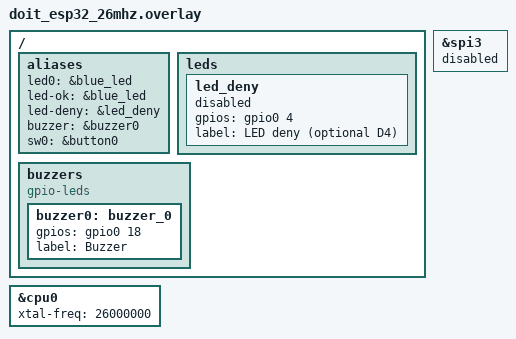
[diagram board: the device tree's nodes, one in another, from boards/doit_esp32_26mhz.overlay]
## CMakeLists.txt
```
# SPDX-License-Identifier: Apache-2.0

cmake_minimum_required(VERSION 3.20.0)
set(DTC_OVERLAY_FILE boards/doit_esp32_26mhz.overlay) #devicetree overlay file
find_package(Zephyr REQUIRED HINTS $ENV{ZEPHYR_BASE})
project(epi_guard)

target_sources(app PRIVATE
	src/main.c
	src/zbus_channels.c
	src/api_client.c
	src/validator.c
	src/actuator.c
	src/actuator_feedback.c
	src/net.c
	src/epi_state.c
	src/epi_names.c
	src/epi_shell.c
	src/epi_config.c
)

if(CONFIG_SETTINGS)
	target_sources(app PRIVATE src/epi_settings.c)
endif()

if(CONFIG_EPI_API_USE_MOCK)
	target_sources(app PRIVATE src/api_client_mock.c)
else()
	target_sources(app PRIVATE src/api_client_http.c)
endif()

if(CONFIG_EPI_HTTP_SERVER OR NOT CONFIG_EPI_API_USE_MOCK)
	target_sources(app PRIVATE src/json_codec.c)
endif()

if(CONFIG_EPI_HTTP_SERVER)
	target_sources(app PRIVATE src/net_http.c src/dashboard_embed.c)
endif()
```

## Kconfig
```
mainmenu "EPI Guard"

source "Kconfig.zephyr"

config EPI_API_USE_MOCK
	bool "Usar mock local da API (sem rede)"
	default y
	help
	  Quando ativo, api_check() usa logica embutida (M1/M2).
	  Desative para cliente HTTP real (M3) — requer WiFi (M4) no hardware.

config EPI_HTTP_SERVER
	bool "Servidor HTTP dashboard (sockets TCP)"
	default n
	depends on NETWORKING && NET_TCP && NET_SOCKETS
	help
	  Servidor HTTP simples em :80 para dashboard e POST /verify.
	  Usa sockets POSIX (mais estavel que CONFIG_HTTP_SERVER no ESP32).
```

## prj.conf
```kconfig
# Core
CONFIG_ZBUS=y
CONFIG_ZBUS_CHANNEL_NAME=y
CONFIG_SHELL=y
CONFIG_LOG=y
CONFIG_LOG_DEFAULT_LEVEL=3

# Console (UART via USB-serial)
CONFIG_CONSOLE=y
CONFIG_UART_CONSOLE=y
CONFIG_SERIAL=y

# GPIO (LED built-in — feedback visual no M1)
CONFIG_GPIO=y

# Stacks
CONFIG_MAIN_STACK_SIZE=2048
CONFIG_SYSTEM_WORKQUEUE_STACK_SIZE=2048

# Shell — edicao de linha (backspace/setas) via VT100
CONFIG_SHELL_VT100_COMMANDS=y
```

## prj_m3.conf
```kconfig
# M3 — cliente HTTP + JSON (combinar com prj.conf; WiFi em prj_wifi.conf)

CONFIG_EPI_API_USE_MOCK=n

# Rede
CONFIG_NETWORKING=y
CONFIG_NET_IPV4=y
CONFIG_NET_IPV6=n
CONFIG_NET_TCP=y
CONFIG_NET_SOCKETS=y
CONFIG_NET_DHCPV4=y
CONFIG_POSIX_API=y
CONFIG_ZVFS_POLL_MAX=4

CONFIG_NET_PKT_RX_COUNT=10
CONFIG_NET_PKT_TX_COUNT=10
CONFIG_NET_BUF_RX_COUNT=20
CONFIG_NET_BUF_TX_COUNT=20
CONFIG_NET_MAX_CONTEXTS=8

CONFIG_HEAP_MEM_POOL_SIZE=65536
CONFIG_MAIN_STACK_SIZE=4096
CONFIG_SYSTEM_WORKQUEUE_STACK_SIZE=4096

# HTTP + JSON
CONFIG_HTTP_CLIENT=y
CONFIG_JSON_LIBRARY=y

# Stacks das threads de rede
CONFIG_NET_TX_STACK_SIZE=2048
CONFIG_NET_RX_STACK_SIZE=2048

CONFIG_TEST_RANDOM_GENERATOR=y
```

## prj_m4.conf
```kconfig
# M4 — settings NVS + WiFi (combinar com prj_m3.conf)

CONFIG_SETTINGS=y
CONFIG_FLASH=y
CONFIG_FLASH_MAP=y
CONFIG_NVS=y
CONFIG_SETTINGS_NVS=y

CONFIG_NET_MGMT=y
CONFIG_NET_MGMT_EVENT=y

CONFIG_WIFI=y
CONFIG_WIFI_LOG_LEVEL_ERR=y
CONFIG_NET_L2_WIFI_MGMT=y
CONFIG_NET_L2_WIFI_SHELL=y
CONFIG_NET_MGMT_EVENT_QUEUE_TIMEOUT=5000
CONFIG_NET_MGMT_EVENT_QUEUE_SIZE=16

CONFIG_NET_SHELL=y
CONFIG_SHELL_STACK_SIZE=4096
CONFIG_COMMON_LIBC_MALLOC_ARENA_SIZE=8192
```

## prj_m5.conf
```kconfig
# M5 — dashboard HTTP via sockets (combinar com prj.conf; prj_m3.conf; prj_m4.conf)

CONFIG_EPI_HTTP_SERVER=y

# Evita acumulo de sockets TIME_WAIT durante testes repetidos no browser
CONFIG_NET_TCP_TIME_WAIT_DELAY=0

# Servidor HTTP (listen + cliente) + cliente API outbound ao mesmo tempo
CONFIG_NET_MAX_CONN=8
CONFIG_NET_MAX_CONTEXTS=12
CONFIG_NET_PKT_RX_COUNT=16
CONFIG_NET_PKT_TX_COUNT=16
CONFIG_NET_BUF_RX_COUNT=32
CONFIG_NET_BUF_TX_COUNT=32
CONFIG_ZVFS_POLL_MAX=8
```

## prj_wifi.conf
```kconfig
# WiFi ESP32 — usar junto com prj_m3.conf (marco M4 completa settings)

CONFIG_WIFI=y
CONFIG_WIFI_LOG_LEVEL_ERR=y
CONFIG_NET_L2_WIFI_MGMT=y
CONFIG_NET_L2_WIFI_SHELL=y
CONFIG_NET_MGMT_EVENT_QUEUE_TIMEOUT=5000
CONFIG_NET_MGMT_EVENT_QUEUE_SIZE=16

CONFIG_NET_SHELL=y
```

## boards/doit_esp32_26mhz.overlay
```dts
/*
 * DOIT ESP32 DevKit — cristal 26 MHz + perifericos EPI Guard.
 *
 * D18 da placa = GPIO18 (buzzer ativo). SPI3 usa GPIO18 por padrao — desabilitado.
 */

#include <zephyr/dt-bindings/gpio/gpio.h>

&cpu0 {
	xtal-freq = <26000000>;
};

&spi3 {
	status = "disabled";
};

/ {
	aliases {
		led0     = &blue_led;
		led-ok   = &blue_led;
		led-deny = &led_deny;
		buzzer   = &buzzer0;
		sw0      = &button0;
	};

	leds {
		led_deny: led_deny {
			gpios = <&gpio0 4 GPIO_ACTIVE_HIGH>;
			label = "LED deny (optional D4)";
			status = "disabled";
		};
	};

	buzzers {
		compatible = "gpio-leds";

		buzzer0: buzzer_0 {
			gpios = <&gpio0 18 GPIO_ACTIVE_HIGH>;
			label = "Buzzer";
		};
	};
};
```

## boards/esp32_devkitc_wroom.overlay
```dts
/*
 * Referencia generica do plano (§5.6) para esp32_devkitc_wroom.
 *
 * Placa DOIT usada no projeto: boards/doit_esp32_26mhz.overlay
 * (CMakeLists.txt aponta DTC_OVERLAY_FILE para esse arquivo).
 *
 * Para montar LED vermelho opcional (led-deny), habilite o no em doit_esp32_26mhz.overlay:
 *   status = "okay";  no nó led_deny (GPIO4 / D4).
 */
```

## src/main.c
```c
/*
 * SPDX-License-Identifier: Apache-2.0
 */

#include <zephyr/kernel.h>
#include <zephyr/logging/log.h>

#if IS_ENABLED(CONFIG_SETTINGS)
#include "epi_config.h"
#include "epi_settings.h"
#endif

#if IS_ENABLED(CONFIG_EPI_HTTP_SERVER)
#include "net_http.h"
#endif

LOG_MODULE_REGISTER(main, LOG_LEVEL_INF);

int main(void)
{
#if IS_ENABLED(CONFIG_SETTINGS)
	int rc;

	rc = epi_settings_init();
	if (rc < 0) {
		LOG_ERR("settings init failed: %d", rc);
	} else {
		rc = epi_settings_load();
		if (rc < 0) {
			LOG_WRN("settings load failed: %d", rc);
		}
		epi_config_sync_from_settings();
	}
#endif

	LOG_INF("EPI Guard firmware - marco M6");
#if IS_ENABLED(CONFIG_EPI_API_USE_MOCK)
	LOG_INF("API: mock local (epi verify sem rede)");
#else
	LOG_INF("API: HTTP client (epi api http://<IP>:3000)");
#endif
#if IS_ENABLED(CONFIG_WIFI)
	LOG_INF("WiFi: epi wifi <ssid> <psk> | epi net");
#endif
#if IS_ENABLED(CONFIG_EPI_HTTP_SERVER)
	LOG_INF("Dashboard: sobe apos WiFi/DHCP (epi status)");
#else
	LOG_INF("Teste: epi verify Gabriel Capacete,Oculos,Cinto,Bota");
#endif

	return 0;
}
```

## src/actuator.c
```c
/*
 * SPDX-License-Identifier: Apache-2.0
 */

#include "actuator_feedback.h"
#include "epi_state.h"
#include "zbus_channels.h"

#include <zephyr/drivers/gpio.h>
#include <zephyr/kernel.h>
#include <zephyr/logging/log.h>
#include <zephyr/zbus/zbus.h>

LOG_MODULE_REGISTER(actuator, LOG_LEVEL_INF);

extern struct zbus_observer actuator_sub;

#define LED0_NODE   DT_ALIAS(led0)
#define BUZZER_NODE DT_ALIAS(buzzer)
#define SW0_NODE    DT_ALIAS(sw0)

#if DT_NODE_HAS_STATUS(LED0_NODE, okay)
static const struct gpio_dt_spec led = GPIO_DT_SPEC_GET(LED0_NODE, gpios);
#define EPI_HAS_LED 1
#else
#define EPI_HAS_LED 0
#endif

#if DT_NODE_HAS_STATUS(BUZZER_NODE, okay)
static const struct gpio_dt_spec buzzer = GPIO_DT_SPEC_GET(BUZZER_NODE, gpios);
#define EPI_HAS_BUZZER 1
#else
#define EPI_HAS_BUZZER 0
#endif

#if DT_NODE_HAS_STATUS(SW0_NODE, okay)
static const struct gpio_dt_spec button = GPIO_DT_SPEC_GET(SW0_NODE, gpios);
#define EPI_HAS_BUTTON 1
#else
#define EPI_HAS_BUTTON 0
#endif

static bool led_ready;
static bool buzzer_ready;
static bool button_ready;

struct feedback_ctx {
	struct k_work work;
	struct verify_result result;
};

static struct feedback_ctx feedback;

static int actuator_gpio_init(void)
{
#if EPI_HAS_LED
	if (gpio_is_ready_dt(&led) && gpio_pin_configure_dt(&led, GPIO_OUTPUT_INACTIVE) == 0) {
		led_ready = true;
	} else {
		LOG_WRN("led0 indisponivel");
	}
#endif

#if EPI_HAS_BUZZER
	if (gpio_is_ready_dt(&buzzer) &&
	    gpio_pin_configure_dt(&buzzer, GPIO_OUTPUT_INACTIVE) == 0) {
		buzzer_ready = true;
		LOG_INF("buzzer em GPIO%d", buzzer.pin);
	} else {
		LOG_WRN("buzzer indisponivel");
	}
#endif

#if EPI_HAS_BUTTON
	if (gpio_is_ready_dt(&button) &&
	    gpio_pin_configure_dt(&button, GPIO_INPUT) == 0) {
		button_ready = true;
		LOG_INF("botao BOOT em GPIO%d", button.pin);
	} else {
		LOG_WRN("botao sw0 indisponivel");
	}
#endif

	return 0;
}

static void led_on(void)
{
#if EPI_HAS_LED
	if (led_ready) {
		gpio_pin_set_dt(&led, 1);
	}
#endif
}

static void led_off(void)
{
#if EPI_HAS_LED
	if (led_ready) {
		gpio_pin_set_dt(&led, 0);
	}
#endif
}

static void buzzer_on(void)
{
#if EPI_HAS_BUZZER
	if (buzzer_ready) {
		gpio_pin_set_dt(&buzzer, 1);
	}
#endif
}

static void buzzer_off(void)
{
#if EPI_HAS_BUZZER
	if (buzzer_ready) {
		gpio_pin_set_dt(&buzzer, 0);
	}
#endif
}

static void beep_ms(uint32_t ms)
{
	buzzer_on();
	k_msleep(ms);
	buzzer_off();
}

static bool button_pressed(void)
{
#if EPI_HAS_BUTTON
	int val;

	if (!button_ready) {
		return false;
	}

	val = gpio_pin_get_dt(&button);
	if (val < 0) {
		return false;
	}

	/* gpio_pin_get_dt: 1 = ativo (pressionado com GPIO_ACTIVE_LOW no DT) */
	return val != 0;
#else
	return false;
#endif
}

static void log_missing(const struct verify_result *res)
{
	if (res->missing_count == 0) {
		return;
	}

	LOG_INF("Faltando:");
	for (uint8_t i = 0; i < res->missing_count; i++) {
		LOG_INF("  - %s", res->missing[i]);
	}
}

static void run_allowed(void)
{
	LOG_INF("LIBERADO - bip curto, LED fixo ~3 s");
	beep_ms(120);
	led_on();
	k_msleep(3000);
	led_off();
}

static void run_denied(const struct verify_result *res)
{
	LOG_INF("NEGADO - bip longo, LED piscando ~3 s");
	log_missing(res);

	beep_ms(900);

	for (int i = 0; i < 6; i++) {
		led_on();
		k_msleep(250);
		led_off();
		k_msleep(250);
	}
}

static void run_unknown(void)
{
	LOG_INF("NAO CADASTRADO - LED azul piscando, buzzer continuo (pressione BOOT para parar)");

	while (!button_pressed()) {
		buzzer_on();
		k_msleep(120);
		buzzer_off();
		k_msleep(80);

		led_on();
		k_msleep(200);
		if (button_pressed()) {
			break;
		}
		led_off();
		k_msleep(200);
	}

	buzzer_off();
	led_off();
	LOG_INF("alarma encerrada (botao pressionado)");
}

static void run_error(void)
{
	LOG_INF("ERRO - 3 bips curtos");

	for (int i = 0; i < 3; i++) {
		beep_ms(120);
		k_msleep(120);
	}
}

static void feedback_handler(struct k_work *work)
{
	struct feedback_ctx *ctx = CONTAINER_OF(work, struct feedback_ctx, work);
	const struct verify_result *res = &ctx->result;

	switch (epi_feedback_from_result(res)) {
	case EPI_FEEDBACK_ERROR:
		run_error();
		break;
	case EPI_FEEDBACK_ALLOWED:
		run_allowed();
		break;
	case EPI_FEEDBACK_DENIED:
		run_denied(res);
		break;
	default:
		run_error();
		break;
	}
}

static void schedule_feedback(const struct verify_result *res)
{
	feedback.result = *res;
	k_work_submit(&feedback.work);
}

static void handle_result(const struct verify_result *res)
{
	enum epi_feedback_kind kind;

	epi_state_store_result(res);
	kind = epi_feedback_from_result(res);

	if (kind == EPI_FEEDBACK_ERROR) {
		schedule_feedback(res);
		return;
	}

	if (kind == EPI_FEEDBACK_UNKNOWN) {
		LOG_INF("result req_id=%u NAO CADASTRADO", res->req_id);
		run_unknown();
		return;
	}

	if (kind == EPI_FEEDBACK_ALLOWED) {
		LOG_INF("result req_id=%u LIBERADO", res->req_id);
	} else {
		LOG_INF("result req_id=%u NEGADO (missing=%u)", res->req_id, res->missing_count);
	}

	schedule_feedback(res);
}

static void actuator_thread(void)
{
	const struct zbus_channel *chan;

	actuator_gpio_init();
	k_work_init(&feedback.work, feedback_handler);
	LOG_INF("actuator thread started");

	while (!zbus_sub_wait(&actuator_sub, &chan, K_FOREVER)) {
		struct verify_result res;

		if (chan != &chan_verify_result) {
			continue;
		}

		if (zbus_chan_read(&chan_verify_result, &res, K_MSEC(500)) < 0) {
			continue;
		}

		handle_result(&res);
	}
}

K_THREAD_DEFINE(actuator_thread_id, 2048, actuator_thread, NULL, NULL, NULL, 7, 0, 0);
```

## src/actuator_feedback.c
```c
/*
 * SPDX-License-Identifier: Apache-2.0
 */

#include "actuator_feedback.h"

enum epi_feedback_kind epi_feedback_from_result(const struct verify_result *res)
{
	if (res == NULL || res->status != VERIFY_OK) {
		return EPI_FEEDBACK_ERROR;
	}

	if (res->unknown_person) {
		return EPI_FEEDBACK_UNKNOWN;
	}

	if (res->allowed) {
		return EPI_FEEDBACK_ALLOWED;
	}

	return EPI_FEEDBACK_DENIED;
}
```

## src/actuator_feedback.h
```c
/*
 * SPDX-License-Identifier: Apache-2.0
 * Mapeamento puro: resultado de verificacao -> padrao de feedback (LED/buzzer).
 */

#ifndef EPI_ACTUATOR_FEEDBACK_H_
#define EPI_ACTUATOR_FEEDBACK_H_

#include "zbus_channels.h"

enum epi_feedback_kind {
	EPI_FEEDBACK_ERROR,
	EPI_FEEDBACK_ALLOWED,
	EPI_FEEDBACK_DENIED,
	EPI_FEEDBACK_UNKNOWN,
};

/** Classifica o resultado para o padrao de atuador (testavel sem GPIO). */
enum epi_feedback_kind epi_feedback_from_result(const struct verify_result *res);

#endif /* EPI_ACTUATOR_FEEDBACK_H_ */
```

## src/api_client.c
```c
/*
 * SPDX-License-Identifier: Apache-2.0
 */

#include "api_client.h"
#include "api_client_internal.h"

#include <errno.h>

#include <zephyr/kernel.h>
#include <zephyr/logging/log.h>

LOG_MODULE_REGISTER(api_client, LOG_LEVEL_INF);

int api_check(const struct verify_request *req, struct verify_result *out)
{
	if (req == NULL || out == NULL) {
		return -EINVAL;
	}

#if IS_ENABLED(CONFIG_EPI_API_USE_MOCK)
	return api_check_mock(req, out);
#else
	return api_check_http(req, out);
#endif
}

int api_ping(void)
{
#if IS_ENABLED(CONFIG_EPI_API_USE_MOCK)
	return 0;
#else
	return api_ping_http();
#endif
}
```

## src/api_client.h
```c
/*
 * SPDX-License-Identifier: Apache-2.0
 */

#ifndef EPI_API_CLIENT_H_
#define EPI_API_CLIENT_H_

#include "zbus_channels.h"

/**
 * Consulta regras de EPI via mock local ou HTTP (api/db.json + POST /check).
 *
 * @return 0 em sucesso, código negativo em falha de rede/parse.
 */
int api_check(const struct verify_request *req, struct verify_result *out);

/** Teste TCP ate a URL configurada (epi api). */
int api_ping(void);

#endif /* EPI_API_CLIENT_H_ */
```

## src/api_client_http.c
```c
/*
 * SPDX-License-Identifier: Apache-2.0
 * Cliente HTTP — POST /check na API Express (M3).
 */

#include "api_client_internal.h"
#include "epi_config.h"
#include "json_codec.h"

#include <errno.h>
#include <stdlib.h>
#include <string.h>

#include <zephyr/kernel.h>
#include <zephyr/logging/log.h>
#include <zephyr/net/http/client.h>
#include <zephyr/net/net_ip.h>
#include <zephyr/posix/arpa/inet.h>
#include <zephyr/posix/sys/socket.h>
#include <zephyr/posix/unistd.h>

LOG_MODULE_DECLARE(api_client);

#if IS_ENABLED(CONFIG_SETTINGS)
#include "epi_settings.h"
#endif

#define HTTP_RECV_BUF_LEN 512
#define HTTP_BODY_BUF_LEN 384
#define HTTP_REQ_TIMEOUT_MS_DEFAULT 10000
#define EPI_API_DEFAULT_PORT 3000

struct http_collect_ctx {
	char body[HTTP_BODY_BUF_LEN];
	size_t body_len;
};

static int parse_api_url(const char *url, char *host, size_t host_len, uint16_t *port)
{
	const char *p = url;
	const char *colon;
	const char *slash;
	size_t hlen;

	if (url == NULL || host == NULL || port == NULL) {
		return -EINVAL;
	}

	if (strncmp(p, "http://", 7) == 0) {
		p += 7;
	}

	colon = strchr(p, ':');
	slash = strchr(p, '/');

	if (colon != NULL && (slash == NULL || colon < slash)) {
		hlen = (size_t)(colon - p);
		if (hlen == 0 || hlen >= host_len) {
			return -EINVAL;
		}
		memcpy(host, p, hlen);
		host[hlen] = '\0';
		*port = (uint16_t)strtoul(colon + 1, NULL, 10);
		if (*port == 0) {
			return -EINVAL;
		}
		return 0;
	}

	hlen = slash != NULL ? (size_t)(slash - p) : strlen(p);
	if (hlen == 0 || hlen >= host_len) {
		return -EINVAL;
	}

	memcpy(host, p, hlen);
	host[hlen] = '\0';
	*port = EPI_API_DEFAULT_PORT;

	return 0;
}

static int http_response_collect(struct http_response *rsp, enum http_final_call final_data,
				 void *user_data)
{
	struct http_collect_ctx *ctx = user_data;
	size_t room;

	if (rsp == NULL || ctx == NULL) {
		return -EINVAL;
	}

	if (rsp->data_len > 0 && rsp->body_frag_start != NULL) {
		room = sizeof(ctx->body) - ctx->body_len - 1;
		if (room > 0) {
			size_t copy = MIN((size_t)rsp->data_len, room);

			memcpy(ctx->body + ctx->body_len, rsp->body_frag_start, copy);
			ctx->body_len += copy;
			ctx->body[ctx->body_len] = '\0';
		}
	}

	if (final_data == HTTP_DATA_FINAL) {
		return 0;
	}

	return 0;
}

static int tcp_connect_ipv4(const char *host, uint16_t port)
{
	struct sockaddr_in addr;
	int sock;
	int ret;

	memset(&addr, 0, sizeof(addr));
	addr.sin_family = AF_INET;
	addr.sin_port = htons(port);

	ret = inet_pton(AF_INET, host, &addr.sin_addr);
	if (ret != 1) {
		LOG_ERR("host invalido (use IP IPv4): %s", host);
		return -EINVAL;
	}

	sock = socket(AF_INET, SOCK_STREAM, IPPROTO_TCP);
	if (sock < 0) {
		int err = errno;

		if (err == ENOENT) {
			LOG_ERR("socket(): sem contexto TCP livre (NET_MAX_CONN/CONTEXTS?)");
		} else {
			LOG_ERR("socket(): errno=%d", err);
		}
		return -err;
	}

	ret = connect(sock, (struct sockaddr *)&addr, sizeof(addr));
	if (ret < 0) {
		int err = errno;

		LOG_ERR("connect(%s:%u): errno=%d", host, port, err);
		close(sock);
		return -err;
	}

	return sock;
}

int api_check_http(const struct verify_request *req, struct verify_result *out)
{
	const char *url = epi_config_get_api_url();
	char host[64];
	char port_str[8];
	uint16_t port;
	char payload[256];
	uint8_t recv_buf[HTTP_RECV_BUF_LEN];
	struct http_collect_ctx collect;
	struct http_request http_req;
	const char *headers[] = {
		"Content-Type: application/json\r\n",
		NULL,
	};
	int sock;
	int ret;

	if (req == NULL || out == NULL) {
		return -EINVAL;
	}

	if (!epi_config_api_ready()) {
		LOG_ERR("URL da API nao configurada (epi api <url>)");
		return -EINVAL;
	}

	ret = parse_api_url(url, host, sizeof(host), &port);
	if (ret < 0) {
		LOG_ERR("URL invalida: %s", url);
		return ret;
	}

	snprintk(port_str, sizeof(port_str), "%u", port);

	ret = json_encode_check_request(req, payload, sizeof(payload));
	if (ret < 0) {
		LOG_ERR("falha ao serializar JSON: %d", ret);
		return ret;
	}

	LOG_INF("POST /check -> %s:%u", host, port);

	sock = tcp_connect_ipv4(host, port);
	if (sock < 0) {
		return sock;
	}

	memset(&collect, 0, sizeof(collect));
	memset(&http_req, 0, sizeof(http_req));

	http_req.method = HTTP_POST;
	http_req.url = "/check";
	http_req.host = host;
	http_req.port = port_str;
	http_req.protocol = "HTTP/1.1";
	http_req.header_fields = headers;
	http_req.payload = payload;
	http_req.payload_len = strlen(payload);
	http_req.response = http_response_collect;
	http_req.recv_buf = recv_buf;
	http_req.recv_buf_len = sizeof(recv_buf);

	ret = http_client_req(sock, &http_req,
#if IS_ENABLED(CONFIG_SETTINGS)
			      (int32_t)epi_settings_get_timeout_ms(),
#else
			      HTTP_REQ_TIMEOUT_MS_DEFAULT,
#endif
			      &collect);
	close(sock);

	if (ret < 0) {
		LOG_ERR("HTTP POST falhou: %d", ret);
		return ret;
	}

	if (collect.body_len == 0) {
		LOG_ERR("resposta HTTP vazia");
		return -EIO;
	}

	memset(out, 0, sizeof(*out));
	ret = json_parse_check_response(collect.body, collect.body_len, out);
	if (ret < 0) {
		LOG_ERR("JSON invalido na resposta: %d", ret);
		return ret;
	}

	LOG_INF("HTTP check %s: allowed=%d unknown=%d missing=%u", req->who, out->allowed,
		out->unknown_person, out->missing_count);

	return 0;
}

int api_ping_http(void)
{
	const char *url = epi_config_get_api_url();
	char host[64];
	uint16_t port;
	int sock;
	int ret;

	if (!epi_config_api_ready()) {
		LOG_ERR("URL da API nao configurada (epi api <url>)");
		return -EINVAL;
	}

	ret = parse_api_url(url, host, sizeof(host), &port);
	if (ret < 0) {
		LOG_ERR("URL invalida: %s", url);
		return ret;
	}

	sock = tcp_connect_ipv4(host, port);
	if (sock < 0) {
		return sock;
	}

	close(sock);
	LOG_INF("ping-api OK: %s:%u", host, port);
	return 0;
}
```

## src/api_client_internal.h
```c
/*
 * SPDX-License-Identifier: Apache-2.0
 */

#ifndef EPI_API_CLIENT_INTERNAL_H_
#define EPI_API_CLIENT_INTERNAL_H_

#include "zbus_channels.h"

int api_check_mock(const struct verify_request *req, struct verify_result *out);
int api_check_http(const struct verify_request *req, struct verify_result *out);
int api_ping_http(void);

#endif /* EPI_API_CLIENT_INTERNAL_H_ */
```

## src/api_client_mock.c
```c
/*
 * SPDX-License-Identifier: Apache-2.0
 * Mock local — espelha api/db.json (§6).
 */

#include "api_client_internal.h"
#include "epi_names.h"

#include <errno.h>
#include <string.h>

#include <zephyr/kernel.h>
#include <zephyr/logging/log.h>
#include <zephyr/sys/util.h>

#if IS_ENABLED(CONFIG_ZTEST)
LOG_MODULE_REGISTER(api_client, LOG_LEVEL_INF);
#else
LOG_MODULE_DECLARE(api_client);
#endif

struct person_rule {
	const char *name;
	const char *required[EPI_MAX_ITEMS];
	uint8_t     required_count;
};

static const struct person_rule people[] = {
	{
		.name = "Gabriel",
		.required = { "Capacete", "Oculos", "Cinto", "Bota" },
		.required_count = 4,
	},
	{
		.name = "Ana",
		.required = { "Capacete", "Luva" },
		.required_count = 2,
	},
	{
		.name = "Joao",
		.required = { "Capacete", "Oculos", "Protetor auricular" },
		.required_count = 3,
	},
};

static bool item_present(const struct verify_request *req, const char *name)
{
	return epi_item_in_list(name, req->items, req->item_count);
}

static void fill_missing(const struct verify_request *req,
			 const char *const *required, uint8_t required_count,
			 struct verify_result *out)
{
	out->missing_count = 0;

	for (uint8_t i = 0; i < required_count && out->missing_count < EPI_MAX_ITEMS; i++) {
		if (!item_present(req, required[i])) {
			epi_name_to_ascii(required[i], out->missing[out->missing_count], EPI_NAME_LEN);
			out->missing_count++;
		}
	}

	out->allowed = (out->missing_count == 0);
}

int api_check_mock(const struct verify_request *req, struct verify_result *out)
{
	const char *const *required = NULL;
	uint8_t required_count = 0;
	bool found = false;

	if (req == NULL || out == NULL) {
		return -EINVAL;
	}

	out->status = VERIFY_OK;
	out->allowed = false;
	out->unknown_person = false;
	out->missing_count = 0;

	for (size_t i = 0; i < ARRAY_SIZE(people); i++) {
		if (strcmp(req->who, people[i].name) == 0) {
			required = people[i].required;
			required_count = people[i].required_count;
			found = true;
			break;
		}
	}

	if (!found) {
		out->unknown_person = true;
		LOG_INF("mock check %s: nao cadastrado", req->who);
		return 0;
	}

	fill_missing(req, required, required_count, out);

	LOG_INF("mock check %s: allowed=%d missing=%u", req->who, out->allowed,
		out->missing_count);

	return 0;
}
```

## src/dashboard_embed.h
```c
/*
 * SPDX-License-Identifier: Apache-2.0
 */

#ifndef EPI_DASHBOARD_EMBED_H_
#define EPI_DASHBOARD_EMBED_H_

#include <stddef.h>
#include <stdint.h>

#define EPI_DASHBOARD_INDEX_HTML_MAX 4096
#define EPI_DASHBOARD_APP_JS_MAX     2048

extern const uint8_t epi_dashboard_index_html[];
extern const size_t epi_dashboard_index_html_len;

extern const uint8_t epi_dashboard_app_js[];
extern const size_t epi_dashboard_app_js_len;

#endif /* EPI_DASHBOARD_EMBED_H_ */
```

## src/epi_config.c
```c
/*
 * SPDX-License-Identifier: Apache-2.0
 */

#include "epi_config.h"

#include <string.h>

#include <zephyr/kernel.h>

#if IS_ENABLED(CONFIG_SETTINGS)
#include "epi_settings.h"
#endif

static char api_url[EPI_API_URL_MAX];
static struct k_mutex config_lock;

static int epi_config_init_fn(void)
{
	k_mutex_init(&config_lock);
	api_url[0] = '\0';
	return 0;
}

SYS_INIT(epi_config_init_fn, APPLICATION, CONFIG_APPLICATION_INIT_PRIORITY);

void epi_config_set_api_url(const char *url)
{
	if (url == NULL) {
		return;
	}

	k_mutex_lock(&config_lock, K_FOREVER);
	strncpy(api_url, url, sizeof(api_url) - 1);
	api_url[sizeof(api_url) - 1] = '\0';
	k_mutex_unlock(&config_lock);

#if IS_ENABLED(CONFIG_SETTINGS)
	(void)epi_settings_set_api_url(url);
#endif
}

void epi_config_sync_from_settings(void)
{
#if IS_ENABLED(CONFIG_SETTINGS)
	char buf[EPI_API_URL_MAX];

	if (epi_settings_get_api_url(buf, sizeof(buf)) == 0 && buf[0] != '\0') {
		k_mutex_lock(&config_lock, K_FOREVER);
		strncpy(api_url, buf, sizeof(api_url) - 1);
		api_url[sizeof(api_url) - 1] = '\0';
		k_mutex_unlock(&config_lock);
	}
#else
	ARG_UNUSED(0);
#endif
}

const char *epi_config_get_api_url(void)
{
	return api_url;
}

bool epi_config_api_ready(void)
{
	return api_url[0] != '\0';
}
```

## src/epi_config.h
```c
/*
 * SPDX-License-Identifier: Apache-2.0
 */

#ifndef EPI_CONFIG_H_
#define EPI_CONFIG_H_

#include <stdbool.h>

#define EPI_API_URL_MAX 96

/** Define URL base da API (ex.: http://192.168.0.10:3000). */
void epi_config_set_api_url(const char *url);

/** Retorna URL configurada ou string vazia. */
const char *epi_config_get_api_url(void);

/** true se modo HTTP ativo e URL nao vazia. */
bool epi_config_api_ready(void);

/** Sincroniza URL em RAM a partir do settings (apos epi_settings_load). */
void epi_config_sync_from_settings(void);

#endif /* EPI_CONFIG_H_ */
```

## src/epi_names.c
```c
/*
 * SPDX-License-Identifier: Apache-2.0
 */

#include "epi_names.h"

#include <stdint.h>
#include <string.h>

#include <zephyr/sys/util.h>

#include "zbus_channels.h"

struct epi_alias {
	const char *canonical;
	const char *ascii;
};

static const struct epi_alias aliases[] = {
	{ "Oculos", "Oculos" },
};

static size_t utf8_fold_char(const char *in, char *out)
{
	unsigned char b = (unsigned char)in[0];

	if (b < 0x80) {
		*out = in[0];
		return 1;
	}

	if ((b & 0xE0) == 0xC0 && in[1] != '\0') {
		unsigned char b2 = (unsigned char)in[1];

		if (b == 0xC3) {
			switch (b2) {
			case 0xA1:
			case 0xA0:
			case 0xA2:
			case 0xA3:
				*out = 'a';
				break;
			case 0xA7:
				*out = 'c';
				break;
			case 0xA9:
			case 0xA8:
				*out = 'e';
				break;
			case 0xAD:
			case 0xAC:
				*out = 'i';
				break;
			case 0xB3:
			case 0xB2:
			case 0xB5:
				*out = 'o';
				break;
			case 0xBA:
			case 0xB9:
				*out = 'u';
				break;
			case 0x81:
				*out = 'A';
				break;
			case 0x87:
				*out = 'C';
				break;
			case 0x89:
				*out = 'E';
				break;
			case 0x8D:
				*out = 'I';
				break;
			case 0x93:
				*out = 'O';
				break;
			case 0x9A:
				*out = 'U';
				break;
			default:
				*out = '?';
				break;
			}
			return 2;
		}
	}

	*out = '?';
	return 1;
}

void epi_name_to_ascii(const char *in, char *out, size_t out_len)
{
	size_t oi = 0;
	size_t consumed;

	if (in == NULL || out == NULL || out_len == 0) {
		return;
	}

	for (size_t i = 0; in[i] != '\0' && oi < out_len - 1; i += consumed) {
		char c;

		consumed = utf8_fold_char(&in[i], &c);
		if (c == '_') {
			c = ' ';
		}
		out[oi++] = c;
	}

	out[oi] = '\0';
}

static void normalize_epi_name(const char *in, char *out, size_t out_len)
{
	epi_name_to_ascii(in, out, out_len);
}

static bool normalized_equal(const char *a, const char *b)
{
	char na[EPI_NAME_LEN];
	char nb[EPI_NAME_LEN];

	normalize_epi_name(a, na, sizeof(na));
	normalize_epi_name(b, nb, sizeof(nb));

	return strcmp(na, nb) == 0;
}

bool epi_name_equal(const char *a, const char *b)
{
	if (a == NULL || b == NULL) {
		return false;
	}

	if (strcmp(a, b) == 0 || normalized_equal(a, b)) {
		return true;
	}

	for (size_t i = 0; i < ARRAY_SIZE(aliases); i++) {
		if ((normalized_equal(a, aliases[i].canonical) &&
		     normalized_equal(b, aliases[i].ascii)) ||
		    (normalized_equal(a, aliases[i].ascii) &&
		     normalized_equal(b, aliases[i].canonical))) {
			return true;
		}
	}

	return false;
}

bool epi_item_in_list(const char *item, const char items[][EPI_NAME_LEN], uint8_t count)
{
	for (uint8_t i = 0; i < count; i++) {
		if (epi_name_equal(item, items[i])) {
			return true;
		}
	}

	return false;
}
```
